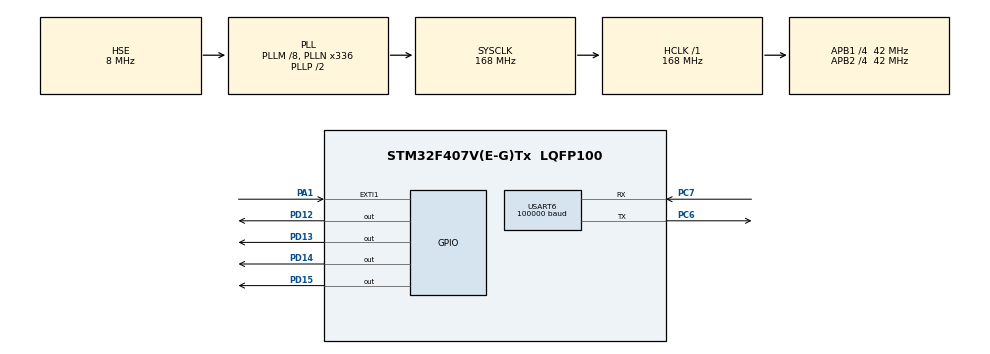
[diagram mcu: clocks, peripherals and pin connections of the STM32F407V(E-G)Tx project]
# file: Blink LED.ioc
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Dma.Request0=USART6_RX
Dma.Request1=USART6_TX
Dma.USART6_RX.0.Direction=DMA_PERIPH_TO_MEMORY
Dma.USART6_RX.0.FIFOMode=DMA_FIFOMODE_DISABLE
Dma.USART6_RX.0.Instance=DMA2_Stream1
Dma.USART6_RX.0.MemDataAlignment=DMA_MDATAALIGN_BYTE
Dma.USART6_RX.0.MemInc=DMA_MINC_ENABLE
Dma.USART6_RX.0.Mode=DMA_CIRCULAR
Dma.USART6_RX.0.PeriphDataAlignment=DMA_PDATAALIGN_BYTE
Dma.USART6_RX.0.PeriphInc=DMA_PINC_DISABLE
Dma.USART6_RX.0.Priority=DMA_PRIORITY_LOW
Dma.USART6_TX.1.Direction=DMA_MEMORY_TO_PERIPH
Dma.USART6_TX.1.FIFOMode=DMA_FIFOMODE_DISABLE
Dma.USART6_TX.1.Instance=DMA2_Stream6
Dma.USART6_TX.1.MemDataAlignment=DMA_MDATAALIGN_BYTE
Dma.USART6_TX.1.MemInc=DMA_MINC_ENABLE
Dma.USART6_TX.1.Mode=DMA_NORMAL
Dma.USART6_TX.1.PeriphDataAlignment=DMA_PDATAALIGN_BYTE
Dma.USART6_TX.1.PeriphInc=DMA_PINC_DISABLE
Dma.USART6_TX.1.Priority=DMA_PRIORITY_LOW
Mcu.Family=STM32F4
Mcu.Name=STM32F407V(E-G)Tx
Mcu.Package=LQFP100
NVIC.DMA2_Stream1_IRQn=true\:0\:0\:false\:false\:true\:false\:true\:true
NVIC.DMA2_Stream6_IRQn=true\:0\:0\:false\:false\:true\:false\:true\:true
NVIC.EXTI1_IRQn=true\:0\:0\:false\:false\:true\:true\:true\:true
NVIC.PriorityGroup=NVIC_PRIORITYGROUP_4
NVIC.TIM8_BRK_TIM12_IRQn=true\:0\:0\:false\:false\:true\:true\:true\:true
NVIC.USART6_IRQn=true\:0\:0\:false\:false\:true\:true\:true\:true
PA1.Signal=GPXTI1
PC6.Mode=Asynchronous
PC6.Signal=USART6_TX
PC7.Mode=Asynchronous
PC7.Signal=USART6_RX
PD12.GPIO_ModeDefaultOutputPP=GPIO_MODE_OUTPUT_PP
PD12.GPIO_PuPd=GPIO_NOPULL
PD12.GPIO_Speed=GPIO_SPEED_FREQ_VERY_HIGH
PD12.PinState=GPIO_PIN_SET
PD12.Signal=GPIO_Output
PD13.GPIO_ModeDefaultOutputPP=GPIO_MODE_OUTPUT_PP
PD13.GPIO_PuPd=GPIO_NOPULL
PD13.GPIO_Speed=GPIO_SPEED_FREQ_VERY_HIGH
PD13.PinState=GPIO_PIN_SET
PD13.Signal=GPIO_Output
PD14.GPIO_ModeDefaultOutputPP=GPIO_MODE_OUTPUT_PP
PD14.GPIO_PuPd=GPIO_NOPULL
PD14.GPIO_Speed=GPIO_SPEED_FREQ_VERY_HIGH
PD14.PinState=GPIO_PIN_SET
PD14.Signal=GPIO_Output
PD15.GPIO_ModeDefaultOutputPP=GPIO_MODE_OUTPUT_PP
PD15.GPIO_PuPd=GPIO_NOPULL
PD15.GPIO_Speed=GPIO_SPEED_FREQ_VERY_HIGH
PD15.PinState=GPIO_PIN_SET
PD15.Signal=GPIO_Output
PH0-OSC_IN.Mode=HSE-External-Oscillator
PH0-OSC_IN.Signal=RCC_OSC_IN
PH1-OSC_OUT.Mode=HSE-External-Oscillator
PH1-OSC_OUT.Signal=RCC_OSC_OUT
ProjectManager.HeapSize=0x200
ProjectManager.StackSize=0x400
ProjectManager.TargetToolchain=MDK-ARM V5.32
RCC.48MHZClocksFreq_Value=84000000
RCC.AHBFreq_Value=168000000
RCC.APB1CLKDivider=RCC_HCLK_DIV4
RCC.APB1Freq_Value=42000000
RCC.APB1TimFreq_Value=84000000
RCC.APB2CLKDivider=RCC_HCLK_DIV4
RCC.APB2Freq_Value=42000000
RCC.APB2TimFreq_Value=84000000
RCC.CortexFreq_Value=168000000
RCC.HCLKFreq_Value=168000000
RCC.HSE_VALUE=8000000
RCC.HSI_VALUE=16000000
RCC.LSE_VALUE=32768
RCC.PLLM=8
RCC.PLLN=336
RCC.PLLSourceVirtual=RCC_PLLSOURCE_HSE
RCC.SYSCLKFreq_VALUE=168000000
RCC.SYSCLKSource=RCC_SYSCLKSOURCE_PLLCLK
RCC.VCOOutputFreq_Value=336000000
TIM12.Period=10
TIM12.Prescaler=42
USART6.BaudRate=100000
USART6.Parity=PARITY_EVEN
USART6.StopBits=STOPBITS_2
USART6.VirtualMode=VM_ASYNC
VP_TIM12_VS_ClockSourceINT.Mode=Internal
VP_TIM2_VS_ClockSourceINT.Mode=Internal
board=Blink LED

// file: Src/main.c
/* USER CODE BEGIN Header */
/**
  ******************************************************************************
  * @file           : main.c
  * @brief          : Main program body
  ******************************************************************************
  * @attention
  *
  * Copyright (c) 2022 STMicroelectronics.
  * All rights reserved.
  *
  * This software is licensed under terms that can be found in the LICENSE file
  * in the root directory of this software component.
  * If no LICENSE file comes with this software, it is provided AS-IS.
  *
  ******************************************************************************
  */
/* USER CODE END Header */
#include "main.h"

TIM_HandleTypeDef htim2;
TIM_HandleTypeDef htim12;

UART_HandleTypeDef huart6;
DMA_HandleTypeDef hdma_usart6_rx;
DMA_HandleTypeDef hdma_usart6_tx;

void SystemClock_Config(void);
static void MX_GPIO_Init(void);
static void MX_DMA_Init(void);
static void MX_TIM12_Init(void);
static void MX_TIM2_Init(void);
static void MX_USART6_UART_Init(void);

	extern uint8_t usart1_data_buffer[30];
int main(void)
{

  /* MCU Configuration--------------------------------------------------------*/

  /* Reset of all peripherals, Initializes the Flash interface and the Systick. */
  HAL_Init();

  /* Configure the system clock */
  SystemClock_Config();

  /* Initialize all configured peripherals */
  MX_GPIO_Init();
  MX_DMA_Init();
  MX_TIM12_Init();
  MX_TIM2_Init();
  MX_USART6_UART_Init();
  /* USER CODE BEGIN 2 */
	HAL_UART_Receive_DMA(&huart6, &usart1_data_buffer[0], 30);
  /* USER CODE END 2 */

  /* Infinite loop */
  while (1)
  {

  }
}

void SystemClock_Config(void)
{
  RCC_OscInitTypeDef RCC_OscInitStruct = {0};
  RCC_ClkInitTypeDef RCC_ClkInitStruct = {0};

  /** Configure the main internal regulator output voltage
  */
  __HAL_RCC_PWR_CLK_ENABLE();
  __HAL_PWR_VOLTAGESCALING_CONFIG(PWR_REGULATOR_VOLTAGE_SCALE1);

  /** Initializes the RCC Oscillators according to the specified parameters
  * in the RCC_OscInitTypeDef structure.
  */
  RCC_OscInitStruct.OscillatorType = RCC_OSCILLATORTYPE_HSE;
  RCC_OscInitStruct.HSEState = RCC_HSE_ON;
  RCC_OscInitStruct.PLL.PLLState = RCC_PLL_ON;
  RCC_OscInitStruct.PLL.PLLSource = RCC_PLLSOURCE_HSE;
  RCC_OscInitStruct.PLL.PLLM = 8;
  RCC_OscInitStruct.PLL.PLLN = 336;
  RCC_OscInitStruct.PLL.PLLP = RCC_PLLP_DIV2;
  RCC_OscInitStruct.PLL.PLLQ = 4;
  if (HAL_RCC_OscConfig(&RCC_OscInitStruct) != HAL_OK)
  {
    Error_Handler();
  }

  /** Initializes the CPU, AHB and APB buses clocks
  */
  RCC_ClkInitStruct.ClockType = RCC_CLOCKTYPE_HCLK|RCC_CLOCKTYPE_SYSCLK
                              |RCC_CLOCKTYPE_PCLK1|RCC_CLOCKTYPE_PCLK2;
  RCC_ClkInitStruct.SYSCLKSource = RCC_SYSCLKSOURCE_PLLCLK;
  RCC_ClkInitStruct.AHBCLKDivider = RCC_SYSCLK_DIV1;
  RCC_ClkInitStruct.APB1CLKDivider = RCC_HCLK_DIV4;
  RCC_ClkInitStruct.APB2CLKDivider = RCC_HCLK_DIV4;

  if (HAL_RCC_ClockConfig(&RCC_ClkInitStruct, FLASH_LATENCY_5) != HAL_OK)
  {
    Error_Handler();
  }
}

static void MX_TIM2_Init(void)
{

  TIM_ClockConfigTypeDef sClockSourceConfig = {0};
  TIM_MasterConfigTypeDef sMasterConfig = {0};

  htim2.Instance = TIM2;
  htim2.Init.Prescaler = 0;
  htim2.Init.CounterMode = TIM_COUNTERMODE_UP;
  htim2.Init.Period = 4294967295;
  htim2.Init.ClockDivision = TIM_CLOCKDIVISION_DIV1;
  htim2.Init.AutoReloadPreload = TIM_AUTORELOAD_PRELOAD_DISABLE;
  if (HAL_TIM_Base_Init(&htim2) != HAL_OK)
  {
    Error_Handler();
  }
  sClockSourceConfig.ClockSource = TIM_CLOCKSOURCE_INTERNAL;
  if (HAL_TIM_ConfigClockSource(&htim2, &sClockSourceConfig) != HAL_OK)
  {
    Error_Handler();
  }
  sMasterConfig.MasterOutputTrigger = TIM_TRGO_RESET;
  sMasterConfig.MasterSlaveMode = TIM_MASTERSLAVEMODE_DISABLE;
  if (HAL_TIMEx_MasterConfigSynchronization(&htim2, &sMasterConfig) != HAL_OK)
  {
    Error_Handler();
  }

}

static void MX_TIM12_Init(void)
{

  TIM_ClockConfigTypeDef sClockSourceConfig = {0};

  htim12.Instance = TIM12;
  htim12.Init.Prescaler = 42;
  htim12.Init.CounterMode = TIM_COUNTERMODE_UP;
  htim12.Init.Period = 10;
  htim12.Init.ClockDivision = TIM_CLOCKDIVISION_DIV1;
  htim12.Init.AutoReloadPreload = TIM_AUTORELOAD_PRELOAD_DISABLE;
  if (HAL_TIM_Base_Init(&htim12) != HAL_OK)
  {
    Error_Handler();
  }
  sClockSourceConfig.ClockSource = TIM_CLOCKSOURCE_INTERNAL;
  if (HAL_TIM_ConfigClockSource(&htim12, &sClockSourceConfig) != HAL_OK)
  {
    Error_Handler();
  }

}

static void MX_USART6_UART_Init(void)
{

  huart6.Instance = USART6;
  huart6.Init.BaudRate = 100000;
  huart6.Init.WordLength = UART_WORDLENGTH_8B;
  huart6.Init.StopBits = UART_STOPBITS_2;
  huart6.Init.Parity = UART_PARITY_EVEN;
  huart6.Init.Mode = UART_MODE_TX_RX;
  huart6.Init.HwFlowCtl = UART_HWCONTROL_NONE;
  huart6.Init.OverSampling = UART_OVERSAMPLING_16;
  if (HAL_UART_Init(&huart6) != HAL_OK)
  {
    Error_Handler();
  }

}

static void MX_DMA_Init(void)
{

  /* DMA controller clock enable */
  __HAL_RCC_DMA2_CLK_ENABLE();

  /* DMA interrupt init */
  /* DMA2_Stream1_IRQn interrupt configuration */
  HAL_NVIC_SetPriority(DMA2_Stream1_IRQn, 0, 0);
  HAL_NVIC_EnableIRQ(DMA2_Stream1_IRQn);
  /* DMA2_Stream6_IRQn interrupt configuration */
  HAL_NVIC_SetPriority(DMA2_Stream6_IRQn, 0, 0);
  HAL_NVIC_EnableIRQ(DMA2_Stream6_IRQn);

}

static void MX_GPIO_Init(void)
{
  GPIO_InitTypeDef GPIO_InitStruct = {0};

  /* GPIO Ports Clock Enable */
  __HAL_RCC_GPIOH_CLK_ENABLE();
  __HAL_RCC_GPIOA_CLK_ENABLE();
  __HAL_RCC_GPIOD_CLK_ENABLE();
  __HAL_RCC_GPIOC_CLK_ENABLE();

  /*Configure GPIO pin Output Level */
  HAL_GPIO_WritePin(GPIOD, GPIO_PIN_12|GPIO_PIN_13|GPIO_PIN_14|GPIO_PIN_15, GPIO_PIN_RESET);

  /*Configure GPIO pin : PA1 */
  GPIO_InitStruct.Pin = GPIO_PIN_1;
  GPIO_InitStruct.Mode = GPIO_MODE_IT_RISING;
  GPIO_InitStruct.Pull = GPIO_NOPULL;
  HAL_GPIO_Init(GPIOA, &GPIO_InitStruct);

  /*Configure GPIO pins : PD12 PD13 PD14 PD15 */
  GPIO_InitStruct.Pin = GPIO_PIN_12|GPIO_PIN_13|GPIO_PIN_14|GPIO_PIN_15;
  GPIO_InitStruct.Mode = GPIO_MODE_OUTPUT_PP;
  GPIO_InitStruct.Pull = GPIO_NOPULL;
  GPIO_InitStruct.Speed = GPIO_SPEED_FREQ_VERY_HIGH;
  HAL_GPIO_Init(GPIOD, &GPIO_InitStruct);

  /* EXTI interrupt init*/
  HAL_NVIC_SetPriority(EXTI1_IRQn, 0, 0);
  HAL_NVIC_EnableIRQ(EXTI1_IRQn);

}

void Error_Handler(void)
{
  __disable_irq();
  while (1)
  {
  }
}
